# ATSAMA5D31 register map
Vendor: Atmel; Series: SAMA5D3; File version: 20130221
Registers are 32-bit, read-write, reset 0x0 unless marked. A register's access mark holds for its fields unless they carry their own. Offsets are from the block's base; [hi:lo] are bit positions; {n}, {i} and the like mark numbered series.

## SPI0 — Serial Peripheral Interface 0
Base 0xF0004000; register names take the prefix SPI0_
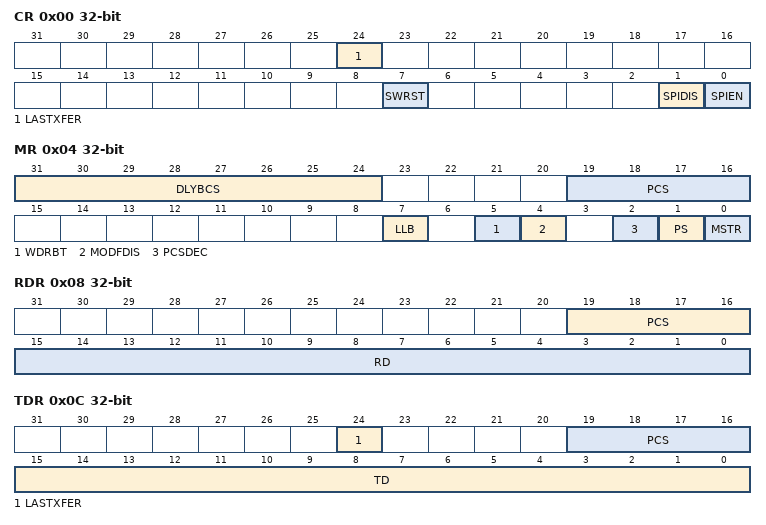
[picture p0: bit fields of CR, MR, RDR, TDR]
0x00 CR wo reset not defined — Control Register
  [24] LASTXFER — Last Transfer
  [7] SWRST — SPI Software Reset
  [1] SPIDIS — SPI Disable
  [0] SPIEN — SPI Enable
0x04 MR — Mode Register
  [31:24] DLYBCS — Delay Between Chip Selects
  [19:16] PCS — Peripheral Chip Select
  [7] LLB — Local Loopback Enable
  [5] WDRBT — Wait Data Read Before Transfer
  [4] MODFDIS — Mode Fault Detection
  [2] PCSDEC — Chip Select Decode
  [1] PS — Peripheral Select
  [0] MSTR — Master/Slave Mode
0x08 RDR ro — Receive Data Register
  [19:16] PCS — Peripheral Chip Select
  [15:0] RD — Receive Data
0x0C TDR wo reset not defined — Transmit Data Register
  [24] LASTXFER — Last Transfer
  [19:16] PCS — Peripheral Chip Select
  [15:0] TD — Transmit Data
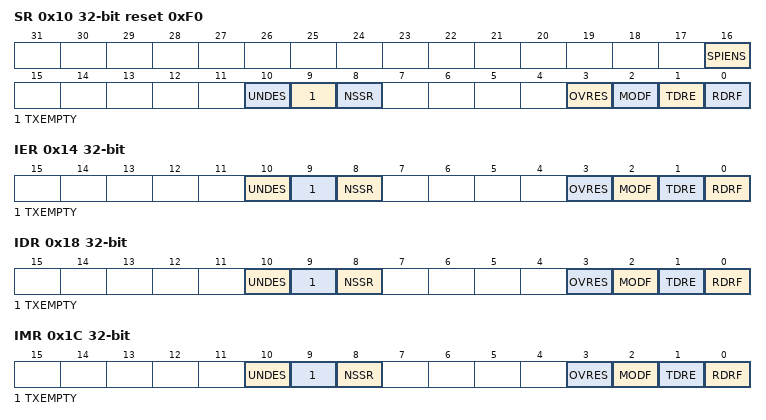
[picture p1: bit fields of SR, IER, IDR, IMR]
0x10 SR ro reset 0xF0 — Status Register
  [16] SPIENS — SPI Enable Status
  [10] UNDES — Underrun Error Status (Slave Mode Only)
  [9] TXEMPTY — Transmission Registers Empty
  [8] NSSR — NSS Rising
  [3] OVRES — Overrun Error Status
  [2] MODF — Mode Fault Error
  [1] TDRE — Transmit Data Register Empty
  [0] RDRF — Receive Data Register Full
0x14 IER wo reset not defined — Interrupt Enable Register
  [10] UNDES — Underrun Error Interrupt Enable
  [9] TXEMPTY — Transmission Registers Empty Enable
  [8] NSSR — NSS Rising Interrupt Enable
  [3] OVRES — Overrun Error Interrupt Enable
  [2] MODF — Mode Fault Error Interrupt Enable
  [1] TDRE — SPI Transmit Data Register Empty Interrupt Enable
  [0] RDRF — Receive Data Register Full Interrupt Enable
0x18 IDR wo reset not defined — Interrupt Disable Register
  [10] UNDES — Underrun Error Interrupt Disable
  [9] TXEMPTY — Transmission Registers Empty Disable
  [8] NSSR — NSS Rising Interrupt Disable
  [3] OVRES — Overrun Error Interrupt Disable
  [2] MODF — Mode Fault Error Interrupt Disable
  [1] TDRE — SPI Transmit Data Register Empty Interrupt Disable
  [0] RDRF — Receive Data Register Full Interrupt Disable
0x1C IMR ro — Interrupt Mask Register
  [10] UNDES — Underrun Error Interrupt Mask
  [9] TXEMPTY — Transmission Registers Empty Mask
  [8] NSSR — NSS Rising Interrupt Mask
  [3] OVRES — Overrun Error Interrupt Mask
  [2] MODF — Mode Fault Error Interrupt Mask
  [1] TDRE — SPI Transmit Data Register Empty Interrupt Mask
  [0] RDRF — Receive Data Register Full Interrupt Mask
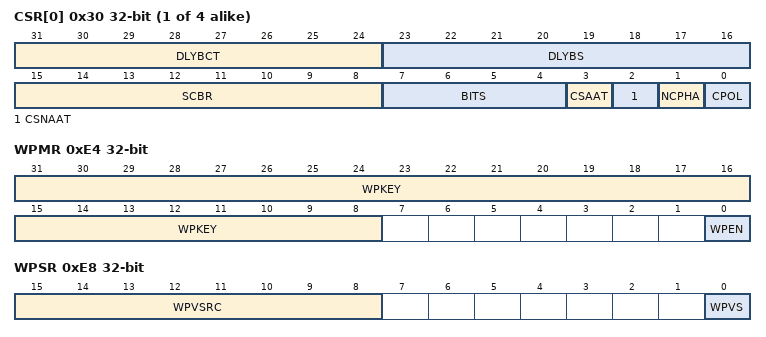
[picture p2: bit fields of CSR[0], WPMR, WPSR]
{0x30+4i} CSR[{i}] (i=0..3) reset not defined — Chip Select Register
  [31:24] DLYBCT — Delay Between Consecutive Transfers
  [23:16] DLYBS — Delay Before SPCK
  [15:8] SCBR — Serial Clock Baud Rate
  [7:4] BITS — Bits Per Transfer
    {v}={v+8}_BIT ({v+8} bits for transfer) (v=0..8)
  [3] CSAAT — Chip Select Active After Transfer
  [2] CSNAAT — Chip Select Not Active After Transfer (Ignored if CSAAT = 1)
  [1] NCPHA — Clock Phase
  [0] CPOL — Clock Polarity
0xE4 WPMR — Write Protection Control Register
  [31:8] WPKEY — Write Protection Key Password
  [0] WPEN — Write Protection Enable
0xE8 WPSR ro — Write Protection Status Register
  [15:8] WPVSRC — Write Protection Violation Source
  [0] WPVS — Write Protection Violation Status

## SPI1 — Serial Peripheral Interface 1
Base 0xF8008000; register names take the prefix SPI1_
Registers as SPI0.

## UART0 — Universal Asynchronous Receiver Transmitter 0
Base 0xF0024000; register names take the prefix UART0_
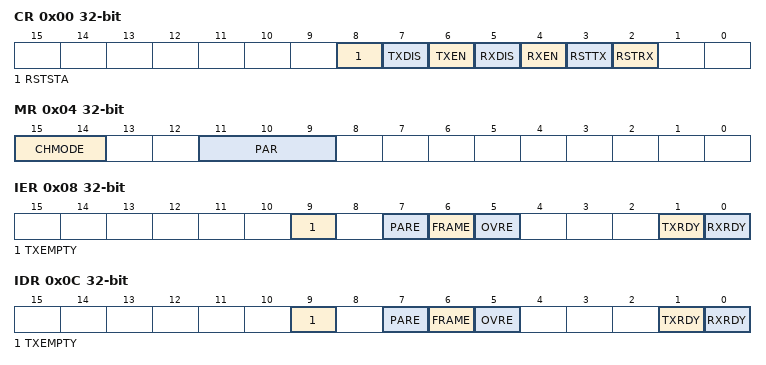
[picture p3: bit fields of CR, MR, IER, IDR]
0x00 CR wo reset not defined — Control Register
  [8] RSTSTA — Reset Status Bits
  [7] TXDIS — Transmitter Disable
  [6] TXEN — Transmitter Enable
  [5] RXDIS — Receiver Disable
  [4] RXEN — Receiver Enable
  [3] RSTTX — Reset Transmitter
  [2] RSTRX — Reset Receiver
0x04 MR — Mode Register
  [15:14] CHMODE — Channel Mode
    0=NORMAL (Normal Mode); 1=AUTOMATIC (Automatic Echo); 2=LOCAL_LOOPBACK; 3=REMOTE_LOOPBACK
  [11:9] PAR — Parity Type
    0=EVEN (Even Parity); 1=ODD (Odd Parity); 2=SPACE (Space: parity forced to 0); 3=MARK (Mark: parity forced to 1); 4=NO (No Parity)
0x08 IER wo reset not defined — Interrupt Enable Register
  [9] TXEMPTY — Enable TXEMPTY Interrupt
  [7] PARE — Enable Parity Error Interrupt
  [6] FRAME — Enable Framing Error Interrupt
  [5] OVRE — Enable Overrun Error Interrupt
  [1] TXRDY — Enable TXRDY Interrupt
  [0] RXRDY — Enable RXRDY Interrupt
0x0C IDR wo reset not defined — Interrupt Disable Register
  [9] TXEMPTY — Disable TXEMPTY Interrupt
  [7] PARE — Disable Parity Error Interrupt
  [6] FRAME — Disable Framing Error Interrupt
  [5] OVRE — Disable Overrun Error Interrupt
  [1] TXRDY — Disable TXRDY Interrupt
  [0] RXRDY — Disable RXRDY Interrupt
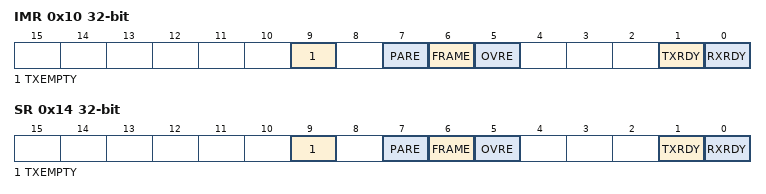
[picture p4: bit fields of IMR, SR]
0x10 IMR ro — Interrupt Mask Register
  [9] TXEMPTY — Mask TXEMPTY Interrupt
  [7] PARE — Mask Parity Error Interrupt
  [6] FRAME — Mask Framing Error Interrupt
  [5] OVRE — Mask Overrun Error Interrupt
  [1] TXRDY — Disable TXRDY Interrupt
  [0] RXRDY — Mask RXRDY Interrupt
0x14 SR ro reset not defined — Status Register
  [9] TXEMPTY — Transmitter Empty
  [7] PARE — Parity Error
  [6] FRAME — Framing Error
  [5] OVRE — Overrun Error
  [1] TXRDY — Transmitter Ready
  [0] RXRDY — Receiver Ready
0x18 RHR ro — Receive Holding Register
  [7:0] RXCHR — Received Character
0x1C THR wo reset not defined — Transmit Holding Register
  [7:0] TXCHR — Character to be Transmitted
0x20 BRGR — Baud Rate Generator Register
  [15:0] CD — Clock Divisor

## UART1 — Universal Asynchronous Receiver Transmitter 1
Base 0xF8028000; register names take the prefix UART1_
Registers as UART0.
